# RTL8710AF register map
Vendor: Realtek Semiconductor; Series: Ameba; File version: 0.1
Realtek RTL8710 Cortex-M3-based WiFi Module
CPU: CM3 r0p0, little endian, no MPU, no FPU, vendor SysTick, 4 interrupt priority bits
Registers are 32-bit, read-write, reset 0x0 unless marked. A register's access mark holds for its fields unless they carry their own. Offsets are from the block's base; lines under a group give offsets from that group; [hi:lo] are bit positions; {n}, {i} and the like mark numbered series; 'fields as' and 'values as' point back to an identical list; <NAME> marks a mode.

## Memory map
0x40000000 SYSCON — System Control Registers
0x40001000 GPIO size 0x400 — General Purpose I/O
0x40002000 Timer size 0x1000 — Timer Control
0x40003000 LOG_UART size 0x400 — UART for Log
0x40003400 I2C2 size 0x400 — I2C port 2
0x40003800 I2C3 size 0x400 — I2C port 3
0x40006000 SPI_FLASH size 0x1000 — SPI Flash Controller
0x40010000 ADC size 0x1000
0x40040000 UART0 size 0x400
0x40040000 SPI0 size 0x400
0x40040800 UART1 size 0x400
0x40040800 SPI_1 size 0x400
0x40044400 I2C1 size 0x400
0x40058000 SDIO size 0x4000 — SDIO Host
0x40060000 GDMA0 size 0x800
0x40061000 GDMA1 size 0x800
0x40063000 I2S1 size 0x400
0x40064000 PCM_0 size 0x400
0x40065000 PCM_1 size 0x400
0x40070000 CRYPTO size 0x4000 — Security Engine
0x40080000 WIFI size 0x40000 — WIFI REG & TX/RX FIFO direct map

## Interrupts
2 TIMER0 (Timer)
3 TIMER1 (Timer)
4 I2C3
5 TIMER2_7 (Timer)
6 SPI0
7 GPIO
8 UART0
9 SPI_FLASH
11 SDIO_HOST (SDIO)
12 SDIO_DEVICE (SDIO)
13 I2S0_PCM0 (PCM_0)
14 I2S1_PCM1 (PCM_1)
15 WL_DMA (WIFI)
16 WL_PROTOCOL (WIFI)
17 CRYPTO
20 GDMA0_CHANNEL0 (GDMA0)
21 GDMA0_CHANNEL1 (GDMA0)
22 GDMA0_CHANNEL2 (GDMA0)
23 GDMA0_CHANNEL3 (GDMA0)
24 GDMA0_CHANNEL4 (GDMA0)
25 GDMA0_CHANNEL5 (GDMA0)
26 GDMA1_CHANNEL0 (GDMA1)
27 GDMA1_CHANNEL1 (GDMA1)
28 GDMA1_CHANNEL2 (GDMA1)
29 GDMA1_CHANNEL3 (GDMA1)
30 GDMA1_CHANNEL4 (GDMA1)
31 GDMA1_CHANNEL5 (GDMA1)
65 I2C1
66 I2C2
72 SPI1 (SPI_1)
80 UART1
88 LOG_UART
89 ADC

## GPIO — General Purpose I/O
Base 0x40001000
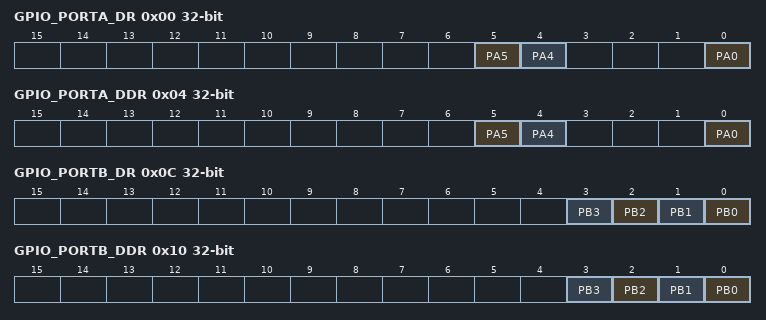
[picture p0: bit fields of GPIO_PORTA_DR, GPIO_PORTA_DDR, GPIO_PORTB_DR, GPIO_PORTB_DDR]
0x00 GPIO_PORTA_DR — GPIO Port A Data Register
  [all] fields
    on write: 0=Low (Low value); 1=High value
  [5] PA5 — GPIOA_5 Data
  [4] PA4 — GPIOA_4 Data
  [0] PA0 — GPIOA_0 Data
0x04 GPIO_PORTA_DDR — GPIO Port A Data Direction Register
  [all] fields
    0=Input (Configure the pin as an input); 1=Output (Configure the pin as an output)
  [5] PA5 — GPIOA_5 Data Direction
  [4] PA4 — GPIOA_4 Data Direction
  [0] PA0 — GPIOA_0 Data Direction
0x08 GPIO_PORTA_CTRL — GPIO Port A Data Source Control
0x0C GPIO_PORTB_DR — GPIO Port B Data Register
  [all] fields
    on write: 0=Low (Low value); 1=High value
  [n] PB{n} (n=0..3) — GPIOB_{n} Data
0x10 GPIO_PORTB_DDR — GPIO Port B Data Direction Register
  [all] fields
    values as the fields of GPIO_PORTA_DDR
  [n] PB{n} (n=0..3) — GPIOB_{n} Data Direction
0x14 GPIO_PORTB_CTRL — GPIO Port B Data Source Control
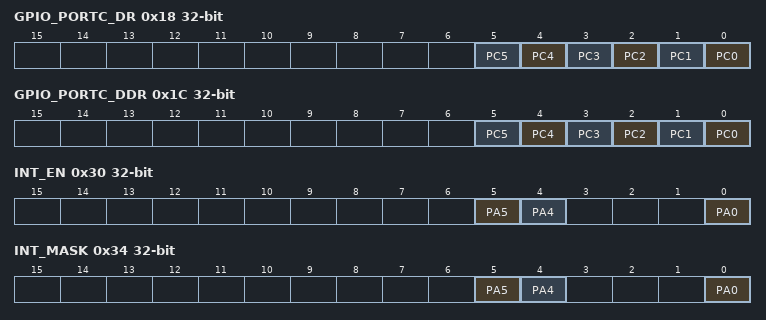
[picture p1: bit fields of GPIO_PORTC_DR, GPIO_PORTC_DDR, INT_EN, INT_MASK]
0x18 GPIO_PORTC_DR — GPIO Port C Data Register
  [all] fields
    on write: 0=Low (Low value); 1=High value
  [n] PC{n} (n=0..5) — GPIOC_{n} Data
0x1C GPIO_PORTC_DDR — GPIO Port C Data Direction Register
  [all] fields
    values as the fields of GPIO_PORTA_DDR
  [n] PC{n} (n=0..5) — GPIOC_{n} Data Direction
0x20 GPIO_PORTC_CTRL — GPIO Port C Data Source Control
0x30 INT_EN — Interrupt Enable
  [5] PA5 — GPIOA_5
  [4] PA4 — GPIOA_4
  [0] PA0 — GPIOA_0
0x34 INT_MASK — Interrupt Mask
  [5] PA5 — GPIOA_5
  [4] PA4 — GPIOA_4
  [0] PA0 — GPIOA_0
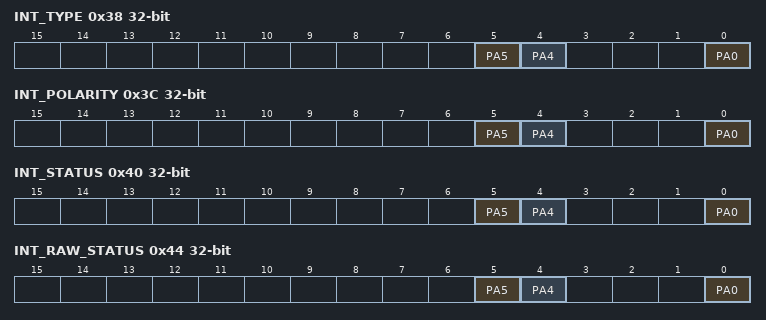
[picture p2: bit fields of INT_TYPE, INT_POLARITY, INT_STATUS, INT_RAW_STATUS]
0x38 INT_TYPE — Interrupt Type (level/edge)
  [5] PA5 — GPIOA_5
  [4] PA4 — GPIOA_4
  [0] PA0 — GPIOA_0
0x3C INT_POLARITY — Interrupt Polarity (low/high)
  [5] PA5 — GPIOA_5
  [4] PA4 — GPIOA_4
  [0] PA0 — GPIOA_0
0x40 INT_STATUS — Interrupt Status
  [5] PA5 — GPIOA_5
  [4] PA4 — GPIOA_4
  [0] PA0 — GPIOA_0
0x44 INT_RAW_STATUS — Interrupt Status Without Mask
  [5] PA5 — GPIOA_5
  [4] PA4 — GPIOA_4
  [0] PA0 — GPIOA_0
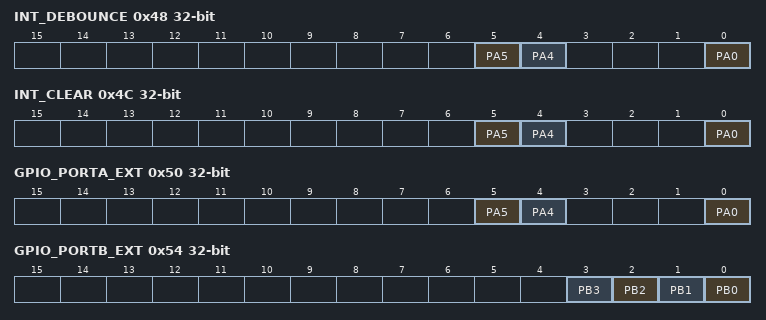
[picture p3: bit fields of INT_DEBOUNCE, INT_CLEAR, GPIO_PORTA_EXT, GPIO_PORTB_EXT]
0x48 INT_DEBOUNCE — Interrupt Debounce
  [5] PA5 — GPIOA_5
  [4] PA4 — GPIOA_4
  [0] PA0 — GPIOA_0
0x4C INT_CLEAR — Interrupt Clear
  [5] PA5 — GPIOA_5
  [4] PA4 — GPIOA_4
  [0] PA0 — GPIOA_0
0x50 GPIO_PORTA_EXT ro — GPIO Port A External Data
  [all] fields
    on read: 0=Low; 1=High
  [5] PA5 — GPIOA_5 Data
  [4] PA4 — GPIOA_4 Data
  [0] PA0 — GPIOA_0 Data
0x54 GPIO_PORTB_EXT ro — GPIO Port B External Data
  [all] fields
    on read: 0=Low; 1=High
  [n] PB{n} (n=0..3) — GPIOB_{n} Data
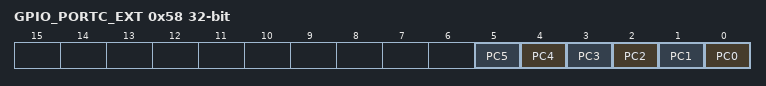
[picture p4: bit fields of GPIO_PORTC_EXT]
0x58 GPIO_PORTC_EXT ro — GPIO Port C External Data
  [all] fields
    on read: 0=Low; 1=High
  [n] PC{n} (n=0..5) — GPIOC_{n} Data
0x60 INT_SYNC — Is level-sensitive interrupt being sync with PCLK

## Licence text in the file
Copyright (c) 2019 David Goodlad Permission is hereby granted, free of charge, to any person obtaining a copy of this software and associated documentation files (the "Software"), to deal in the Software without restriction, including without limitation the rights to use, copy, modify, merge, publish, distribute, sublicense, and/or sell copies of the Software, and to permit persons to whom the Software is furnished to do so, subject to the following conditions: The above copyright notice and this permission notice shall be included in all copies or substantial portions of the Software. THE SOFTWARE IS PROVIDED "AS IS", WITHOUT WARRANTY OF ANY KIND, EXPRESS OR IMPLIED, INCLUDING BUT NOT LIMITED TO THE WARRANTIES OF MERCHANTABILITY, FITNESS FOR A PARTICULAR PURPOSE AND NONINFRINGEMENT. IN NO EVENT SHALL THE AUTHORS OR COPYRIGHT HOLDERS BE LIABLE FOR ANY CLAIM, DAMAGES OR OTHER LIABILITY, WHETHER IN AN ACTION OF CONTRACT, TORT OR OTHERWISE, ARISING FROM, OUT OF OR IN CONNECTION WITH THE SOFTWARE OR THE USE OR OTHER DEALINGS IN THE SOFTWARE.
